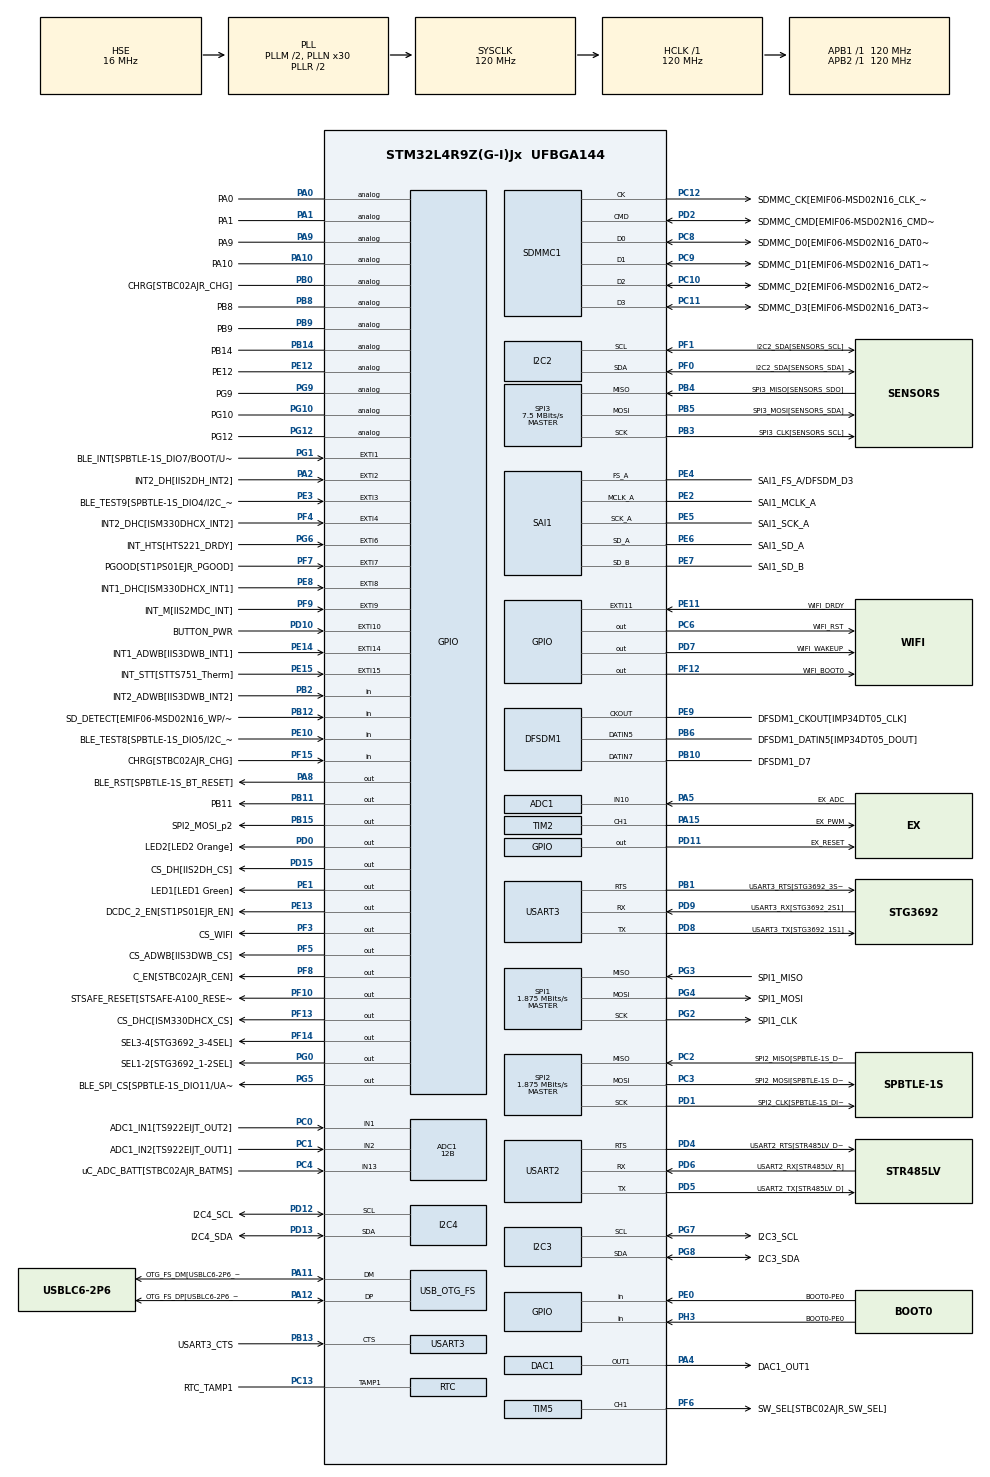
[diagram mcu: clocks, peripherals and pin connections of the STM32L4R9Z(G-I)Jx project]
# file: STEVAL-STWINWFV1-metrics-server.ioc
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PD12.GPIO_Label=I2C4_SCL
ADC1.LowPowerAutoWait=DISABLE
PB10.GPIO_PuPd=GPIO_PULLDOWN
PG8.Signal=I2C3_SDA
PG0.Signal=GPIO_Output
SAI1.Instance-SAI_A_MasterWithClock=SAI$Index_Block_A
PA15\ (JTDI).Signal=S_TIM2_CH1
PC15-OSC32_OUT\ (PC15).Mode=LSE-External-Oscillator
PC14-OSC32_IN\ (PC14).Mode=LSE-External-Oscillator
PF7.Signal=GPXTI7
SPI1.Direction=SPI_DIRECTION_2LINES
RCC.APB2TimFreq_Value=120000000
PB6.Signal=S_DATAIN5DFSDM1
Dma.ADC1.0.Direction=DMA_PERIPH_TO_MEMORY
SPI1.CalculateBaudRate=1.875 MBits/s
PD0.Signal=GPIO_Output
PD8.Signal=USART3_TX
PE1.Signal=GPIO_Output
Dma.ADC1.0.MemDataAlignment=DMA_MDATAALIGN_HALFWORD
ADC1.ScanConvMode=ADC_SCAN_DISABLE
PF1.GPIO_Label=I2C2_SDA[SENSORS_SCL]
PG2.Mode=Full_Duplex_Master
RCC.RTCClockSelection=RCC_RTCCLKSOURCE_LSE
PD1.GPIO_Label=SPI2_CLK[SPBTLE-1S_DIO0/SPI_CLK]
PB12.GPIO_Label=SD_DETECT[EMIF06-MSD02N16_WP/CD]
PF12.GPIO_Label=WIFI_BOOT0
PA13\ (JTMS/SWDIO).GPIO_Label=SWDIO
PC4.GPIO_Label=uC_ADC_BATT[STBC02AJR_BATMS]
PE9.Signal=S_CKOUTDFSDM1
PB1.GPIO_Label=USART3_RTS[STG3692_3S2]
SPI1.DataSize=SPI_DATASIZE_8BIT
PE4.GPIO_Label=SAI1_FS_A/DFSDM_D3
PG4.GPIO_Label=SPI1_MOSI
PC9.Mode=SD_4_bits_Wide_bus
PA8.Signal=GPIO_Output
LTDC.HSync=1
PA0.Signal=GPIO_Analog
PG3.Mode=Full_Duplex_Master
Mcu.Package=UFBGA144
PB9.Signal=GPIO_Analog
PB1.Signal=USART3_RTS
SPI2.Mode=SPI_MODE_MASTER
ADC1.OversamplingMode=DISABLE
SPI3.Mode=SPI_MODE_MASTER
PD12.Signal=I2C4_SCL
PA10.Signal=GPIO_Analog
PE12.GPIO_Label=PE12
PC11.Mode=SD_4_bits_Wide_bus
LTDC.VSync=1
RCC.APB1TimFreq_Value=120000000
PB13.Mode=CTS_RTS
PA4.GPIO_Label=DAC1_OUT1
ADC1.EOCSelection=ADC_EOC_SINGLE_CONV
SAI1.Synchro-SAI_A_MasterWithClock=SAI_ASYNCHRONOUS
PD15.Signal=GPIO_Output
RCC.HSI48_VALUE=48000000
PG12.Signal=GPIO_Analog
SH.S_DATAIN5DFSDM1.0=DFSDM1_DATIN5,PDM_SPI_input_from_ch5_and_internal_clock
TIM5.Channel-Forced\ Output1\ CH1=TIM_CHANNEL_1
SAI1.MClockEnable-SAI_A_MasterWithClock=SAI_MASTERCLOCK_ENABLE
PG5.Signal=GPIO_Output
ADC1.OffsetNumber-0\#ChannelRegularConversion=ADC_OFFSET_NONE
PC13.Signal=RTC_TAMP1
PB6.GPIO_PuPd=GPIO_PULLDOWN
PC2.Signal=SPI2_MISO
SAI1.ErrorAudioFreq-SAI_A_MasterWithClock=-75.0 %
SPI1.CLKPhase=SPI_PHASE_2EDGE
PD6.Mode=Asynchronous
PF8.GPIO_Label=C_EN[STBC02AJR_CEN]
PD10.Signal=GPXTI10
PB8.GPIO_Label=PB8
PA8.GPIO_Label=BLE_RST[SPBTLE-1S_BT_RESET]
SH.COMP_DAC11_group.0=DAC1_OUT1,DAC_OUT1
PE8.GPIO_Label=INT1_DHC[ISM330DHCX_INT1]
Dma.ADC1.0.Priority=DMA_PRIORITY_MEDIUM
NVIC.I2C2_ER_IRQn=true\:0\:0\:false\:false\:true\:true\:true
PD8.Mode=Asynchronous
SAI1.VirtualMode-SAI_A_MasterWithClock=VM_MASTER
PB14.Signal=GPIO_Analog
PA5.Signal=ADCx_IN10
PC12.Mode=SD_4_bits_Wide_bus
PE1.GPIO_Label=LED1[LED1 Green]
PD1.Mode=Full_Duplex_Master
NVIC.DFSDM1_FLT0_IRQn=true\:0\:0\:false\:false\:true\:true\:true
PE14.Signal=GPXTI14
PE6.Mode=SAI_A_MasterWithClock
PB15.GPIO_Label=SPI2_MOSI_p2
SPI1.Mode=SPI_MODE_MASTER
PG7.GPIO_Label=I2C3_SCL
PF4.GPIO_Label=INT2_DHC[ISM330DHCX_INT2]
PA1.GPIO_Label=PA1
PF13.Signal=GPIO_Output
ADC1.ExternalTrigConv=ADC_SOFTWARE_START
PC8.Mode=SD_4_bits_Wide_bus
ADC1.master=1
PA5.GPIO_Label=EX_ADC
PE5.GPIO_Label=SAI1_SCK_A
PC12.GPIO_Label=SDMMC_CK[EMIF06-MSD02N16_CLK_In]
Dma.ADC1.0.RequestNumber=1
ProjectManager.HeapSize=0x200
PB1.Mode=CTS_RTS
NVIC.PriorityGroup=NVIC_PRIORITYGROUP_4
PF0.GPIO_Label=I2C2_SDA[SENSORS_SDA]
PE3.Signal=GPXTI3
PF4.Signal=GPXTI4
PD2.Signal=SDMMC1_CMD
Mcu.Family=STM32L4
PG8.Mode=I2C
ADC1.Overrun=ADC_OVR_DATA_PRESERVED
ADC1.ContinuousConvMode=DISABLE
PG2.Signal=SPI1_SCK
PH0-OSC_IN\ (PH0).Signal=RCC_OSC_IN
Dma.ADC1.0.Polarity=HAL_DMAMUX_REQUEST_GEN_RISING
PE11.GPIO_Label=WIFI_DRDY
VP_TIM5_VS_OPM.Mode=OPM_bit
PA0.GPIO_Label=PA0
PD0.GPIO_Label=LED2[LED2 Orange]
PA11.Mode=Device_Only
I2C2.Timeout=0x000085B8
PG5.GPIO_Label=BLE_SPI_CS[SPBTLE-1S_DIO11/UART_RXD]
PB13.GPIO_Label=USART3_CTS
PB15.Signal=GPIO_Output
PD9.Mode=Asynchronous
PD13.Signal=I2C4_SDA
SAI1.VirtualMode-SAI_B_SyncSlave=VM_SLAVE
SPI3.CLKPolarity=SPI_POLARITY_HIGH
ADC1.Resolution=ADC_RESOLUTION_12B
PD5.Mode=Asynchronous
ADC1.Channel-0\#ChannelRegularConversion=ADC_CHANNEL_VREFINT
PH1-OSC_OUT\ (PH1).Mode=HSE-External-Oscillator
RCC.HSE_VALUE=16000000
LTDC.VBP=1
PB5.Mode=Full_Duplex_Master
PC11.GPIO_Label=SDMMC_D3[EMIF06-MSD02N16_DAT3_In]
TIM2.Channel-PWM\ Generation1\ CH1=TIM_CHANNEL_1
PD13.GPIO_Label=I2C4_SDA
PD5.GPIO_Label=USART2_TX[STR485LV_D]
PF8.Signal=GPIO_Output
PG0.GPIO_Label=SEL1-2[STG3692_1-2SEL]
I2C3.Timing=0x307075B1
SH.ADCx_IN1.0=ADC1_IN1,IN1-Single-Ended
PB5.GPIO_Label=SPI3_MOSI[SENSORS_SDA]
SH.S_TIM5_CH1.0=TIM5_CH1,Forced Output1 CH1
PC5.Signal=SYS_WKUP5
RCC.CK48CLockSelection=RCC_USBCLKSOURCE_HSI48
PE7.Signal=SAI1_SD_B
PD6.Signal=USART2_RX
Dma.Request0=ADC1
PF3.GPIO_Label=CS_WIFI
PE2.GPIO_Label=SAI1_MCLK_A
PG2.GPIO_Label=SPI1_CLK
PH1-OSC_OUT\ (PH1).GPIO_Label=OSC_OUT
PB3\ (JTDO/TRACESWO).GPIO_Label=SPI3_CLK[SENSORS_SCL]
RCC.MSI_VALUE=4000000
SH.ADCx_IN13.0=ADC1_IN13,IN13-Single-Ended
SH.S_TIM2_CH1.0=TIM2_CH1,PWM Generation1 CH1
LTDC.VFP=1
PD15.GPIO_Label=CS_DH[IIS2DH_CS]
PG7.Signal=I2C3_SCL
PC9.GPIO_Label=SDMMC_D1[EMIF06-MSD02N16_DAT1_In]
PC11.Signal=SDMMC1_D3
RCC.DSITX_Div=1
PC8.Signal=SDMMC1_D0
PC10.Mode=SD_4_bits_Wide_bus
PC2.Mode=Full_Duplex_Master
PE14.GPIO_Label=INT1_ADWB[IIS3DWB_INT1]
PD9.Signal=USART3_RX
PA12.GPIO_Label=OTG_FS_DP[USBLC6-2P6_D1]
PH1-OSC_OUT\ (PH1).Signal=RCC_OSC_OUT
PD8.GPIO_Label=USART3_TX[STG3692_1S1]
PG8.GPIO_Label=I2C3_SDA
SAI1.RealAudioFreq-SAI_A_MasterWithClock=48.0 KHz
Dma.ADC1.0.PeriphDataAlignment=DMA_PDATAALIGN_HALFWORD
PF6.Signal=S_TIM5_CH1
PB10.GPIO_Label=DFSDM1_D7
ADC1.EnableAnalogWatchDog3=false
ADC1.EnableAnalogWatchDog2=false
ADC1.EnableAnalogWatchDog1=false
RCC.USBFreq_Value=48000000
PF9.GPIO_Label=INT_M[IIS2MDC_INT]
PD10.GPIO_Label=BUTTON_PWR
PA1.Signal=GPIO_Analog
PD2.Mode=SD_4_bits_Wide_bus
board=STEVAL-STWINKT1
SPI3.CLKPhase=SPI_PHASE_2EDGE
RCC.VCOOutputFreq_Value=240000000
PE5.Mode=SAI_A_MasterWithClock
RCC.ADCFreq_Value=76800000
PC1.GPIO_Label=ADC1_IN2[TS922EIJT_OUT1]
RCC.PLLDSIODF=DSI_PLL_OUT_DIV2
PF15.GPIO_Label=CHRG[STBC02AJR_CHG]
PF1.Signal=I2C2_SCL
ADC1.NbrOfConversion=1
PC13.Mode=Tamper 1 enabled
PA15\ (JTDI).GPIO_Label=EX_PWM
PE0.Signal=GPIO_Input
PE7.GPIO_Label=SAI1_SD_B
PE12.Signal=GPIO_Analog
RCC.SYSCLKFreq_VALUE=120000000
PC14-OSC32_IN\ (PC14).Signal=RCC_OSC32_IN
Dma.ADC1.0.MemInc=DMA_MINC_ENABLE
PB2.GPIO_Label=INT2_ADWB[IIS3DWB_INT2]
NVIC.I2C2_EV_IRQn=true\:0\:0\:false\:false\:true\:true\:true
RCC.HSI_VALUE=16000000
PH0-OSC_IN\ (PH0).GPIO_Label=OSC_IN
RCC.PLLN=30
ADC1.DataAlign=ADC_DATAALIGN_RIGHT
DFSDM1.Filter_regChannel_FIL0=DFSDM_CHANNEL_5
PB12.Signal=GPIO_Input
PB4\ (NJTRST).Signal=SPI3_MISO
SPI3.Direction=SPI_DIRECTION_2LINES
SPI3.VirtualType=VM_MASTER
SPI1.VirtualType=VM_MASTER
SPI2.VirtualType=VM_MASTER
PG4.Signal=SPI1_MOSI
PC12.Signal=SDMMC1_CK
PB14.GPIO_Label=PB14
PG6.GPIO_Label=INT_HTS[HTS221_DRDY]
PC6.GPIO_Label=WIFI_RST
VP_RTC_VS_RTC_Activate.Mode=RTC_Enabled
PB6.GPIO_Label=DFSDM1_DATIN5[IMP34DT05_DOUT]
PC5.Mode=SYS_WakeUp4
PB13.Signal=USART3_CTS
PD6.GPIO_Label=USART2_RX[STR485LV_R]
PE6.GPIO_Label=SAI1_SD_A
PF6.GPIO_Label=SW_SEL[STBC02AJR_SW_SEL]
RCC.SYSCLKSource=RCC_SYSCLKSOURCE_PLLCLK
USART3.VirtualMode-Asynchronous=VM_ASYNC
PA14\ (JTCK/SWCLK).Signal=SYS_JTCK-SWCLK
I2C4.Timing=0x307075B1
PE2.Mode=SAI_A_MasterWithClock
PD4.Signal=USART2_RTS
PC3.Signal=SPI2_MOSI
PE5.Signal=SAI1_SCK_A
PF10.GPIO_Label=STSAFE_RESET[STSAFE-A100_RESET]
PB2.Signal=GPIO_Input
VP_ADC1_Vref_Input.Mode=IN-Vrefint
Dma.ADC1.0.PeriphInc=DMA_PINC_DISABLE
SPI2.CalculateBaudRate=1.875 MBits/s
PE2.Signal=SAI1_MCLK_A
PA14\ (JTCK/SWCLK).Mode=Serial_Wire
PF3.Signal=GPIO_Output
PE10.Signal=GPIO_Input
ADC1.SamplingTime-0\#ChannelRegularConversion=ADC_SAMPLETIME_2CYCLES_5
PH3-BOOT0.Signal=GPIO_Input
RCC.SDMMCClockSelection=RCC_SDIOCLKSOURCE_CLK48
ADC1.EnableInjectedConversion=DISABLE
PA14\ (JTCK/SWCLK).GPIO_Label=SWDCLK
PD4.Mode=RTS_Only
PF14.Signal=GPIO_Output
PE10.GPIO_Label=BLE_TEST8[SPBTLE-1S_DIO5/I2C_SDA]
PH0-OSC_IN\ (PH0).Mode=HSE-External-Oscillator
Dma.ADC1.0.EventEnable=DISABLE
Dma.ADC1.0.Instance=DMA1_Channel1
PC15-OSC32_OUT\ (PC15).GPIO_Label=OSC32_OUT
ADC1.Rank-0\#ChannelRegularConversion=1
PD9.GPIO_Label=USART3_RX[STG3692_2S1]
Dma.ADC1.0.SyncRequestNumber=1
PG9.Signal=GPIO_Analog
PA9.GPIO_Label=PA9
PC6.Signal=GPIO_Output
PB11.GPIO_Label=PB11
PD7.Signal=GPIO_Output
PD1.Signal=SPI2_SCK
PA11.GPIO_Label=OTG_FS_DM[USBLC6-2P6_D2]
PF14.GPIO_Label=SEL3-4[STG3692_3-4SEL]
ADC1.ExternalTrigConvEdge=ADC_EXTERNALTRIGCONVEDGE_NONE
PC0.Signal=ADCx_IN1
PF13.GPIO_Label=CS_DHC[ISM330DHCX_CS]
PG10.Signal=GPIO_Analog
PC14-OSC32_IN\ (PC14).GPIO_Label=OSC32_IN
PF1.Mode=I2C
Dma.ADC1.0.SignalID=NONE
PA9.Signal=GPIO_Analog
PE9.GPIO_Label=DFSDM1_CKOUT[IMP34DT05_CLK]
PB10.Signal=S_DATAIN7DFSDM1
PE15.Signal=GPXTI15
PE8.Signal=GPXTI8
ADC1.DMAContinuousRequests=DISABLE
PB4\ (NJTRST).Mode=Full_Duplex_Master
PA4.Signal=COMP_DAC11_group
PB5.Signal=SPI3_MOSI
PD12.Mode=I2C
PE13.GPIO_Label=DCDC_2_EN[ST1PS01EJR_EN]
PD11.Signal=GPIO_Output
PA11.Signal=USB_OTG_FS_DM
PF9.Signal=GPXTI9
PB3\ (JTDO/TRACESWO).Mode=Full_Duplex_Master
ADC1.EnableRegularConversion=ENABLE
PC3.GPIO_Label=SPI2_MOSI[SPBTLE-1S_DIO3/SPI_MOSI]
SPI2.DataSize=SPI_DATASIZE_8BIT
PB4\ (NJTRST).GPIO_Label=SPI3_MISO[SENSORS_SDO]
NVIC.DMA1_Channel1_IRQn=true\:0\:0\:false\:false\:true\:false\:true
PG3.GPIO_Label=SPI1_MISO
PB6.GPIO_Speed=GPIO_SPEED_FREQ_VERY_HIGH
PB0.Signal=GPIO_Analog
PC1.Signal=ADCx_IN2
PD2.GPIO_Label=SDMMC_CMD[EMIF06-MSD02N16_CMD_In]
PG10.GPIO_Label=PG10
PA13\ (JTMS/SWDIO).Signal=SYS_JTMS-SWDIO
PF6.GPIO_Speed=GPIO_SPEED_FREQ_HIGH
PC3.Mode=Full_Duplex_Master
RCC.CortexFreq_Value=120000000
PG6.Signal=GPXTI6
PB10.GPIO_Speed=GPIO_SPEED_FREQ_VERY_HIGH
LTDC.HBP=1
SH.ADCx_IN2.0=ADC1_IN2,IN2-Single-Ended
PC10.Signal=SDMMC1_D2
I2C2.Timing=0x307075B1
PH3-BOOT0.GPIO_Label=BOOT0-PE0
PC0.GPIO_Label=ADC1_IN1[TS922EIJT_OUT2]
PE9.GPIO_Speed=GPIO_SPEED_FREQ_VERY_HIGH
PB0.GPIO_Label=CHRG[STBC02AJR_CHG]
PC13.GPIO_Label=RTC_TAMP1
PB11.Signal=GPIO_Output
ProjectManager.StackSize=0x400
PA12.Signal=USB_OTG_FS_DP
SPI2.CLKPolarity=SPI_POLARITY_LOW
PG4.Mode=Full_Duplex_Master
PD11.GPIO_Label=EX_RESET 
RCC.HCLKFreq_Value=120000000
PF12.Signal=GPIO_Output
RCC.AHBFreq_Value=120000000
SPI2.BaudRatePrescaler=SPI_BAUDRATEPRESCALER_64
SPI3.DataSize=SPI_DATASIZE_8BIT
USART2.VirtualMode-Asynchronous=VM_ASYNC
SH.S_DATAIN7DFSDM1.0=DFSDM1_DATIN7,PDM_SPI_input_from_ch7_and_internal_clock
PE13.Signal=GPIO_Output
PF7.GPIO_Label=PGOOD[ST1PS01EJR_PGOOD]
PA10.GPIO_Label=PA10
LTDC.HFP=1
PE4.Mode=SAI_A_MasterWithClock
LTDC.ActiveW=800
PE4.Signal=SAI1_FS_A
PD7.GPIO_Label=WIFI_WAKEUP
PA2.GPIO_Label=INT2_DH[IIS2DH_INT2]
PF5.GPIO_Label=CS_ADWB[IIS3DWB_CS]
USB_OTG_FS.VirtualMode=Device_Only
SPI2.CLKPhase=SPI_PHASE_2EDGE
PE0.GPIO_Label=BOOT0-PE0
PF5.Signal=GPIO_Output
SAI1.Synchro-SAI_B_SyncSlave=SAI_SYNCHRONOUS
SPI2.Direction=SPI_DIRECTION_2LINES
PF0.Signal=I2C2_SDA
SPI1.BaudRatePrescaler=SPI_BAUDRATEPRESCALER_64
PC2.GPIO_Label=SPI2_MISO[SPBTLE-1S_DIO2/SPI_MISO]
RCC.PLLSAI1R=RCC_PLLR_DIV4
RCC.PLLSAI1P=RCC_PLLP_DIV25
RCC.PLLSAI1Q=RCC_PLLQ_DIV4
RCC.PLLSAI1N=96
RCC.PLLSourceVirtual=RCC_PLLSOURCE_HSE
PA13\ (JTMS/SWDIO).Mode=Serial_Wire
PB9.GPIO_Label=PB9
PC10.GPIO_Label=SDMMC_D2[EMIF06-MSD02N16_DAT2_In]
PG3.Signal=SPI1_MISO
PG1.Signal=GPXTI1
PC4.Signal=ADCx_IN13
ADC1.DiscontinuousConvMode=DISABLE
PD5.Signal=USART2_TX
PC15-OSC32_OUT\ (PC15).Signal=RCC_OSC32_OUT
PC8.GPIO_Label=SDMMC_D0[EMIF06-MSD02N16_DAT0_In]
PE15.GPIO_Label=INT_STT[STTS751_Therm]
PB3\ (JTDO/TRACESWO).Signal=SPI3_SCK
ProjectManager.TargetToolchain=STM32CubeIDE
Dma.ADC1.0.Mode=DMA_CIRCULAR
Dma.ADC1.0.SyncSignalID=NONE
PD13.Mode=I2C
PF2.Signal=I2C2_SMBA
PG7.Mode=I2C
PE11.Signal=GPXTI11
PG9.GPIO_Label=PG9
PG1.GPIO_Label=BLE_INT[SPBTLE-1S_DIO7/BOOT/UART_CTS]
Dma.ADC1.0.SyncPolarity=HAL_DMAMUX_SYNC_NO_EVENT
RCC.APB2Freq_Value=120000000
SPI3.CalculateBaudRate=7.5 MBits/s
PD4.GPIO_Label=USART2_RTS[STR485LV_DE]
PF10.Signal=GPIO_Output
SH.S_CKOUTDFSDM1.0=DFSDM1_CKOUT,PDM_SPI_input_from_ch7_and_internal_clock
SH.S_CKOUTDFSDM1.1=DFSDM1_CKOUT,PDM_SPI_input_from_ch5_and_internal_clock
SPI3.BaudRatePrescaler=SPI_BAUDRATEPRESCALER_16
SH.S_CKOUTDFSDM1.2=DFSDM1_CKOUT,CKOUT
PF15.Signal=GPIO_Input
PE6.Signal=SAI1_SD_A
Mcu.Name=STM32L4R9Z(G-I)Jx
PA2.Signal=GPXTI2
PE7.Mode=SAI_B_SyncSlave
RCC.PLLM2=5
RCC.PLLM1=2
RCC.PLLM3=2
PA12.Mode=Device_Only
PC5.GPIO_Label=PC5/WKUP5
SAI1.Instance-SAI_B_SyncSlave=SAI$Index_Block_B
Dma.ADC1.0.SyncEnable=DISABLE
SH.ADCx_IN10.0=ADC1_IN10,IN10-Single-Ended
PF0.Mode=I2C
PG12.GPIO_Label=PG12
VP_LTDC_DSIMode.Mode=RGB888
ADC1.NbrOfConversionFlag=1
PB8.Signal=GPIO_Analog
PE3.GPIO_Label=BLE_TEST9[SPBTLE-1S_DIO4/I2C_CLK]
PC9.Signal=SDMMC1_D1
RCC.APB1Freq_Value=120000000
ADC1.ClockPrescaler=ADC_CLOCK_ASYNC_DIV1
PE9.GPIO_PuPd=GPIO_PULLDOWN
PF2.GPIO_Label=I2C2_SMBA[STTS751_EV]

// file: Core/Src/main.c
/* USER CODE BEGIN Header */
/**
  ******************************************************************************
  * @file           : main.c
  * @brief          : Main program body
  ******************************************************************************
  * @attention
  *
  * <h2><center>&copy; Copyright (c) 2021 STMicroelectronics.
  * All rights reserved.</center></h2>
  *
  * This software component is licensed by ST under BSD 3-Clause license,
  * the "License"; You may not use this file except in compliance with the
  * License. You may obtain a copy of the License at:
  *                        opensource.org/licenses/BSD-3-Clause
  *
  ******************************************************************************
  */
/* USER CODE END Header */
#include "main.h"

/* USER CODE BEGIN PTD */
typedef union {
  int16_t i16bit;
  uint8_t u8bit[2];
} axis1bit16_t;

typedef union {
  int32_t i32bit;
  uint8_t u8bit[4];
} axis1bit32_t;

typedef union {
  int16_t i16bit[3];
  uint8_t u8bit[6];
} axis3bit16_t;
/* USER CODE END PTD */

/* USER CODE BEGIN PM */
typedef struct {
	float x0;
	float y0;
	float x1;
	float y1;
} lin_t;

float linear_interpolation(lin_t *lin, int16_t x) {
	return ((lin->y1 - lin->y0) * x + ((lin->x1 * lin->y0) - (lin->x0 * lin->y1))) / (lin->x1 - lin->x0);
}
/* USER CODE END PM */

ADC_HandleTypeDef hadc1;
DMA_HandleTypeDef hdma_adc1;

DAC_HandleTypeDef hdac1;

DFSDM_Filter_HandleTypeDef hdfsdm1_filter0;
DFSDM_Channel_HandleTypeDef hdfsdm1_channel5;
DFSDM_Channel_HandleTypeDef hdfsdm1_channel7;

I2C_HandleTypeDef hi2c2;
I2C_HandleTypeDef hi2c3;
I2C_HandleTypeDef hi2c4;

LTDC_HandleTypeDef hltdc;

RTC_HandleTypeDef hrtc;

SAI_HandleTypeDef hsai_BlockA1;
SAI_HandleTypeDef hsai_BlockB1;

SD_HandleTypeDef hsd1;

SPI_HandleTypeDef hspi1;
SPI_HandleTypeDef hspi2;
SPI_HandleTypeDef hspi3;

TIM_HandleTypeDef htim2;
TIM_HandleTypeDef htim5;

UART_HandleTypeDef huart2;
UART_HandleTypeDef huart3;

PCD_HandleTypeDef hpcd_USB_OTG_FS;

/* USER CODE BEGIN PV */
static uint8_t whoamI;
lin_t lin_hum;
lin_t lin_temp;
stmdev_ctx_t hts221Driver;
/* USER CODE END PV */

void SystemClock_Config(void);
static void MX_GPIO_Init(void);
static void MX_DMA_Init(void);
static void MX_ADC1_Init(void);
static void MX_DAC1_Init(void);
static void MX_DFSDM1_Init(void);
static void MX_I2C2_Init(void);
static void MX_I2C3_Init(void);
static void MX_I2C4_Init(void);
static void MX_LTDC_Init(void);
static void MX_RTC_Init(void);
static void MX_SAI1_Init(void);
static void MX_SDMMC1_SD_Init(void);
static void MX_SPI1_Init(void);
static void MX_SPI2_Init(void);
static void MX_SPI3_Init(void);
static void MX_TIM2_Init(void);
static void MX_TIM5_Init(void);
static void MX_USART2_UART_Init(void);
static void MX_USART3_UART_Init(void);
static void MX_USB_OTG_FS_PCD_Init(void);
/* USER CODE BEGIN PFP */
HAL_StatusTypeDef Init_HTS221(void);
static int32_t hts221_read(void *handle, uint8_t reg, uint8_t *bufp, uint16_t len);
static int32_t hts221_write(void *handle, uint8_t reg, uint8_t *bufp, uint16_t len);
/* USER CODE END PFP */

int main(void)
{
  /* USER CODE BEGIN 1 */
  hts221_reg_t reg_HTS221;
  static axis1bit16_t data_raw_temperature_HTS221;
  static float temperature_degC_HTS221;
  uint8_t buf[12];
  /* USER CODE END 1 */

  /* MCU Configuration--------------------------------------------------------*/

  /* Reset of all peripherals, Initializes the Flash interface and the Systick. */

  HAL_Init();

  /* Configure the system clock */
  SystemClock_Config();

  /* Initialize all configured peripherals */
  MX_GPIO_Init();
  MX_DMA_Init();
  MX_ADC1_Init();
  MX_DAC1_Init();
  MX_DFSDM1_Init();
  MX_I2C2_Init();
  MX_I2C3_Init();
  MX_I2C4_Init();
  MX_LTDC_Init();
  MX_RTC_Init();
  MX_SAI1_Init();
  MX_SDMMC1_SD_Init();
  MX_SPI1_Init();
  MX_SPI2_Init();
  MX_SPI3_Init();
  MX_TIM2_Init();
  MX_TIM5_Init();
  MX_USART2_UART_Init();
  MX_USART3_UART_Init();
  MX_USB_OTG_FS_PCD_Init();
  /* USER CODE BEGIN 2 */
  hts221Driver.handle = &hi2c2;
  hts221Driver.read_reg = hts221_read;
  hts221Driver.write_reg = hts221_write;

  Init_HTS221();
  /* USER CODE END 2 */

  /* Infinite loop */
  while (1)
  {

    /* USER CODE BEGIN 3 */
    if (reg_HTS221.status_reg.t_da) {
      memset(data_raw_temperature_HTS221.u8bit, 0x00, sizeof(int16_t));
      hts221_temperature_raw_get(&hts221Driver, data_raw_temperature_HTS221.u8bit);
      temperature_degC_HTS221 = linear_interpolation(&lin_temp, data_raw_temperature_HTS221.i16bit);
    }
    sprintf((char*)buf, "%f °C\r\n", temperature_degC_HTS221);
    HAL_UART_Transmit(&huart2, buf, strlen((char*)buf), HAL_MAX_DELAY);
    HAL_Delay(1000);
  }
  /* USER CODE END 3 */
}

void SystemClock_Config(void)
{
  RCC_OscInitTypeDef RCC_OscInitStruct = {0};
  RCC_ClkInitTypeDef RCC_ClkInitStruct = {0};
  RCC_PeriphCLKInitTypeDef PeriphClkInit = {0};

  /** Configure the main internal regulator output voltage
  */
  if (HAL_PWREx_ControlVoltageScaling(PWR_REGULATOR_VOLTAGE_SCALE1_BOOST) != HAL_OK)
  {
    Error_Handler();
  }
  /** Configure LSE Drive Capability
  */
  HAL_PWR_EnableBkUpAccess();
  __HAL_RCC_LSEDRIVE_CONFIG(RCC_LSEDRIVE_LOW);
  /** Initializes the RCC Oscillators according to the specified parameters
  * in the RCC_OscInitTypeDef structure.
  */
  RCC_OscInitStruct.OscillatorType = RCC_OSCILLATORTYPE_HSI48|RCC_OSCILLATORTYPE_HSE
                              |RCC_OSCILLATORTYPE_LSE;
  RCC_OscInitStruct.HSEState = RCC_HSE_ON;
  RCC_OscInitStruct.LSEState = RCC_LSE_ON;
  RCC_OscInitStruct.HSI48State = RCC_HSI48_ON;
  RCC_OscInitStruct.PLL.PLLState = RCC_PLL_ON;
  RCC_OscInitStruct.PLL.PLLSource = RCC_PLLSOURCE_HSE;
  RCC_OscInitStruct.PLL.PLLM = 2;
  RCC_OscInitStruct.PLL.PLLN = 30;
  RCC_OscInitStruct.PLL.PLLP = RCC_PLLP_DIV2;
  RCC_OscInitStruct.PLL.PLLQ = RCC_PLLQ_DIV2;
  RCC_OscInitStruct.PLL.PLLR = RCC_PLLR_DIV2;
  if (HAL_RCC_OscConfig(&RCC_OscInitStruct) != HAL_OK)
  {
    Error_Handler();
  }
  /** Initializes the CPU, AHB and APB buses clocks
  */
  RCC_ClkInitStruct.ClockType = RCC_CLOCKTYPE_HCLK|RCC_CLOCKTYPE_SYSCLK
                              |RCC_CLOCKTYPE_PCLK1|RCC_CLOCKTYPE_PCLK2;
  RCC_ClkInitStruct.SYSCLKSource = RCC_SYSCLKSOURCE_PLLCLK;
  RCC_ClkInitStruct.AHBCLKDivider = RCC_SYSCLK_DIV1;
  RCC_ClkInitStruct.APB1CLKDivider = RCC_HCLK_DIV1;
  RCC_ClkInitStruct.APB2CLKDivider = RCC_HCLK_DIV1;

  if (HAL_RCC_ClockConfig(&RCC_ClkInitStruct, FLASH_LATENCY_5) != HAL_OK)
  {
    Error_Handler();
  }
  PeriphClkInit.PeriphClockSelection = RCC_PERIPHCLK_RTC|RCC_PERIPHCLK_USART2
                              |RCC_PERIPHCLK_USART3|RCC_PERIPHCLK_SAI1
                              |RCC_PERIPHCLK_I2C2|RCC_PERIPHCLK_I2C3
                              |RCC_PERIPHCLK_I2C4|RCC_PERIPHCLK_DFSDM1
                              |RCC_PERIPHCLK_USB|RCC_PERIPHCLK_SDMMC1
                              |RCC_PERIPHCLK_ADC|RCC_PERIPHCLK_LTDC;
  PeriphClkInit.Usart2ClockSelection = RCC_USART2CLKSOURCE_PCLK1;
  PeriphClkInit.Usart3ClockSelection = RCC_USART3CLKSOURCE_PCLK1;
  PeriphClkInit.I2c2ClockSelection = RCC_I2C2CLKSOURCE_PCLK1;
  PeriphClkInit.I2c3ClockSelection = RCC_I2C3CLKSOURCE_PCLK1;
  PeriphClkInit.I2c4ClockSelection = RCC_I2C4CLKSOURCE_PCLK1;
  PeriphClkInit.Sai1ClockSelection = RCC_SAI1CLKSOURCE_PLLSAI1;
  PeriphClkInit.AdcClockSelection = RCC_ADCCLKSOURCE_PLLSAI1;
  PeriphClkInit.Dfsdm1ClockSelection = RCC_DFSDM1CLKSOURCE_PCLK;
  PeriphClkInit.RTCClockSelection = RCC_RTCCLKSOURCE_LSE;
  PeriphClkInit.UsbClockSelection = RCC_USBCLKSOURCE_HSI48;
  PeriphClkInit.Sdmmc1ClockSelection = RCC_SDMMC1CLKSOURCE_HSI48;
  PeriphClkInit.LtdcClockSelection = RCC_LTDCCLKSOURCE_PLLSAI2_DIV2;
  PeriphClkInit.PLLSAI2.PLLSAI2Source = RCC_PLLSOURCE_HSE;
  PeriphClkInit.PLLSAI2.PLLSAI2M = 2;
  PeriphClkInit.PLLSAI2.PLLSAI2N = 8;
  PeriphClkInit.PLLSAI2.PLLSAI2P = RCC_PLLP_DIV2;
  PeriphClkInit.PLLSAI2.PLLSAI2R = RCC_PLLR_DIV2;
  PeriphClkInit.PLLSAI2.PLLSAI2Q = RCC_PLLQ_DIV2;
  PeriphClkInit.PLLSAI2.PLLSAI2ClockOut = RCC_PLLSAI2_LTDCCLK;
  PeriphClkInit.PLLSAI1.PLLSAI1Source = RCC_PLLSOURCE_HSE;
  PeriphClkInit.PLLSAI1.PLLSAI1M = 5;
  PeriphClkInit.PLLSAI1.PLLSAI1N = 96;
  PeriphClkInit.PLLSAI1.PLLSAI1P = RCC_PLLP_DIV25;
  PeriphClkInit.PLLSAI1.PLLSAI1Q = RCC_PLLQ_DIV4;
  PeriphClkInit.PLLSAI1.PLLSAI1R = RCC_PLLR_DIV4;
  PeriphClkInit.PLLSAI1.PLLSAI1ClockOut = RCC_PLLSAI1_SAI1CLK|RCC_PLLSAI1_ADC1CLK;
  if (HAL_RCCEx_PeriphCLKConfig(&PeriphClkInit) != HAL_OK)
  {
    Error_Handler();
  }
}

static void MX_ADC1_Init(void)
{

  ADC_ChannelConfTypeDef sConfig = {0};

  /** Common config
  */
  hadc1.Instance = ADC1;
  hadc1.Init.ClockPrescaler = ADC_CLOCK_ASYNC_DIV1;
  hadc1.Init.Resolution = ADC_RESOLUTION_12B;
  hadc1.Init.DataAlign = ADC_DATAALIGN_RIGHT;
  hadc1.Init.ScanConvMode = ADC_SCAN_DISABLE;
  hadc1.Init.EOCSelection = ADC_EOC_SINGLE_CONV;
  hadc1.Init.LowPowerAutoWait = DISABLE;
  hadc1.Init.ContinuousConvMode = DISABLE;
  hadc1.Init.NbrOfConversion = 1;
  hadc1.Init.DiscontinuousConvMode = DISABLE;
  hadc1.Init.ExternalTrigConv = ADC_SOFTWARE_START;
  hadc1.Init.ExternalTrigConvEdge = ADC_EXTERNALTRIGCONVEDGE_NONE;
  hadc1.Init.DMAContinuousRequests = DISABLE;
  hadc1.Init.Overrun = ADC_OVR_DATA_PRESERVED;
  hadc1.Init.OversamplingMode = DISABLE;
  if (HAL_ADC_Init(&hadc1) != HAL_OK)
  {
    Error_Handler();
  }
  /** Configure Regular Channel
  */
  sConfig.Channel = ADC_CHANNEL_VREFINT;
  sConfig.Rank = ADC_REGULAR_RANK_1;
  sConfig.SamplingTime = ADC_SAMPLETIME_2CYCLES_5;
  sConfig.SingleDiff = ADC_SINGLE_ENDED;
  sConfig.OffsetNumber = ADC_OFFSET_NONE;
  sConfig.Offset = 0;
  if (HAL_ADC_ConfigChannel(&hadc1, &sConfig) != HAL_OK)
  {
    Error_Handler();
  }

}

static void MX_DAC1_Init(void)
{

  DAC_ChannelConfTypeDef sConfig = {0};

  /** DAC Initialization
  */
  hdac1.Instance = DAC1;
  if (HAL_DAC_Init(&hdac1) != HAL_OK)
  {
    Error_Handler();
  }
  /** DAC channel OUT1 config
  */
  sConfig.DAC_SampleAndHold = DAC_SAMPLEANDHOLD_DISABLE;
  sConfig.DAC_Trigger = DAC_TRIGGER_NONE;
  sConfig.DAC_HighFrequency = DAC_HIGH_FREQUENCY_INTERFACE_MODE_DISABLE;
  sConfig.DAC_OutputBuffer = DAC_OUTPUTBUFFER_ENABLE;
  sConfig.DAC_ConnectOnChipPeripheral = DAC_CHIPCONNECT_DISABLE;
  sConfig.DAC_UserTrimming = DAC_TRIMMING_FACTORY;
  if (HAL_DAC_ConfigChannel(&hdac1, &sConfig, DAC_CHANNEL_1) != HAL_OK)
  {
    Error_Handler();
  }

}

static void MX_DFSDM1_Init(void)
{

  hdfsdm1_filter0.Instance = DFSDM1_Filter0;
  hdfsdm1_filter0.Init.RegularParam.Trigger = DFSDM_FILTER_SW_TRIGGER;
  hdfsdm1_filter0.Init.RegularParam.FastMode = DISABLE;
  hdfsdm1_filter0.Init.RegularParam.DmaMode = DISABLE;
  hdfsdm1_filter0.Init.FilterParam.SincOrder = DFSDM_FILTER_FASTSINC_ORDER;
  hdfsdm1_filter0.Init.FilterParam.Oversampling = 1;
  hdfsdm1_filter0.Init.FilterParam.IntOversampling = 1;
  if (HAL_DFSDM_FilterInit(&hdfsdm1_filter0) != HAL_OK)
  {
    Error_Handler();
  }
  hdfsdm1_channel5.Instance = DFSDM1_Channel5;
  hdfsdm1_channel5.Init.OutputClock.Activation = ENABLE;
  hdfsdm1_channel5.Init.OutputClock.Selection = DFSDM_CHANNEL_OUTPUT_CLOCK_SYSTEM;
  hdfsdm1_channel5.Init.OutputClock.Divider = 2;
  hdfsdm1_channel5.Init.Input.Multiplexer = DFSDM_CHANNEL_EXTERNAL_INPUTS;
  hdfsdm1_channel5.Init.Input.DataPacking = DFSDM_CHANNEL_STANDARD_MODE;
  hdfsdm1_channel5.Init.Input.Pins = DFSDM_CHANNEL_SAME_CHANNEL_PINS;
  hdfsdm1_channel5.Init.SerialInterface.Type = DFSDM_CHANNEL_SPI_RISING;
  hdfsdm1_channel5.Init.SerialInterface.SpiClock = DFSDM_CHANNEL_SPI_CLOCK_INTERNAL;
  hdfsdm1_channel5.Init.Awd.FilterOrder = DFSDM_CHANNEL_FASTSINC_ORDER;
  hdfsdm1_channel5.Init.Awd.Oversampling = 1;
  hdfsdm1_channel5.Init.Offset = 0;
  hdfsdm1_channel5.Init.RightBitShift = 0x00;
  if (HAL_DFSDM_ChannelInit(&hdfsdm1_channel5) != HAL_OK)
  {
    Error_Handler();
  }
  hdfsdm1_channel7.Instance = DFSDM1_Channel7;
  hdfsdm1_channel7.Init.OutputClock.Activation = ENABLE;
  hdfsdm1_channel7.Init.OutputClock.Selection = DFSDM_CHANNEL_OUTPUT_CLOCK_SYSTEM;
  hdfsdm1_channel7.Init.OutputClock.Divider = 2;
  hdfsdm1_channel7.Init.Input.Multiplexer = DFSDM_CHANNEL_EXTERNAL_INPUTS;
  hdfsdm1_channel7.Init.Input.DataPacking = DFSDM_CHANNEL_STANDARD_MODE;
  hdfsdm1_channel7.Init.Input.Pins = DFSDM_CHANNEL_SAME_CHANNEL_PINS;
  hdfsdm1_channel7.Init.SerialInterface.Type = DFSDM_CHANNEL_SPI_RISING;
  hdfsdm1_channel7.Init.SerialInterface.SpiClock = DFSDM_CHANNEL_SPI_CLOCK_INTERNAL;
  hdfsdm1_channel7.Init.Awd.FilterOrder = DFSDM_CHANNEL_FASTSINC_ORDER;
  hdfsdm1_channel7.Init.Awd.Oversampling = 1;
  hdfsdm1_channel7.Init.Offset = 0;
  hdfsdm1_channel7.Init.RightBitShift = 0x00;
  if (HAL_DFSDM_ChannelInit(&hdfsdm1_channel7) != HAL_OK)
  {
    Error_Handler();
  }
  if (HAL_DFSDM_FilterConfigRegChannel(&hdfsdm1_filter0, DFSDM_CHANNEL_5, DFSDM_CONTINUOUS_CONV_ON) != HAL_OK)
  {
    Error_Handler();
  }

}

static void MX_I2C2_Init(void)
{

  hi2c2.Instance = I2C2;
  hi2c2.Init.Timing = 0x307075B1;
  hi2c2.Init.OwnAddress1 = 0;
  hi2c2.Init.AddressingMode = I2C_ADDRESSINGMODE_7BIT;
  hi2c2.Init.DualAddressMode = I2C_DUALADDRESS_DISABLE;
  hi2c2.Init.OwnAddress2 = 0;
  hi2c2.Init.OwnAddress2Masks = I2C_OA2_NOMASK;
  hi2c2.Init.GeneralCallMode = I2C_GENERALCALL_DISABLE;
  hi2c2.Init.NoStretchMode = I2C_NOSTRETCH_DISABLE;
  if (HAL_I2C_Init(&hi2c2) != HAL_OK)
  {
    Error_Handler();
  }
  /** Configure Analogue filter
  */
  if (HAL_I2CEx_ConfigAnalogFilter(&hi2c2, I2C_ANALOGFILTER_ENABLE) != HAL_OK)
  {
    Error_Handler();
  }
  /** Configure Digital filter
  */
  if (HAL_I2CEx_ConfigDigitalFilter(&hi2c2, 0) != HAL_OK)
  {
    Error_Handler();
  }

}

static void MX_I2C3_Init(void)
{

  hi2c3.Instance = I2C3;
  hi2c3.Init.Timing = 0x307075B1;
  hi2c3.Init.OwnAddress1 = 0;
  hi2c3.Init.AddressingMode = I2C_ADDRESSINGMODE_7BIT;
  hi2c3.Init.DualAddressMode = I2C_DUALADDRESS_DISABLE;
  hi2c3.Init.OwnAddress2 = 0;
  hi2c3.Init.OwnAddress2Masks = I2C_OA2_NOMASK;
  hi2c3.Init.GeneralCallMode = I2C_GENERALCALL_DISABLE;
  hi2c3.Init.NoStretchMode = I2C_NOSTRETCH_DISABLE;
  if (HAL_I2C_Init(&hi2c3) != HAL_OK)
  {
    Error_Handler();
  }
  /** Configure Analogue filter
  */
  if (HAL_I2CEx_ConfigAnalogFilter(&hi2c3, I2C_ANALOGFILTER_ENABLE) != HAL_OK)
  {
    Error_Handler();
  }
  /** Configure Digital filter
  */
  if (HAL_I2CEx_ConfigDigitalFilter(&hi2c3, 0) != HAL_OK)
  {
    Error_Handler();
  }

}

static void MX_I2C4_Init(void)
{

  hi2c4.Instance = I2C4;
  hi2c4.Init.Timing = 0x307075B1;
  hi2c4.Init.OwnAddress1 = 0;
  hi2c4.Init.AddressingMode = I2C_ADDRESSINGMODE_7BIT;
  hi2c4.Init.DualAddressMode = I2C_DUALADDRESS_DISABLE;
  hi2c4.Init.OwnAddress2 = 0;
  hi2c4.Init.OwnAddress2Masks = I2C_OA2_NOMASK;
  hi2c4.Init.GeneralCallMode = I2C_GENERALCALL_DISABLE;
  hi2c4.Init.NoStretchMode = I2C_NOSTRETCH_DISABLE;
  if (HAL_I2C_Init(&hi2c4) != HAL_OK)
  {
    Error_Handler();
  }
  /** Configure Analogue filter
  */
  if (HAL_I2CEx_ConfigAnalogFilter(&hi2c4, I2C_ANALOGFILTER_ENABLE) != HAL_OK)
  {
    Error_Handler();
  }
  /** Configure Digital filter
  */
  if (HAL_I2CEx_ConfigDigitalFilter(&hi2c4, 0) != HAL_OK)
  {
    Error_Handler();
  }

}

static void MX_LTDC_Init(void)
{

  LTDC_LayerCfgTypeDef pLayerCfg = {0};
  LTDC_LayerCfgTypeDef pLayerCfg1 = {0};

  hltdc.Instance = LTDC;
  hltdc.Init.HSPolarity = LTDC_HSPOLARITY_AL;
  hltdc.Init.VSPolarity = LTDC_VSPOLARITY_AL;
  hltdc.Init.DEPolarity = LTDC_DEPOLARITY_AL;
  hltdc.Init.PCPolarity = LTDC_PCPOLARITY_IPC;
  hltdc.Init.HorizontalSync = 0;
  hltdc.Init.VerticalSync = 0;
  hltdc.Init.AccumulatedHBP = 1;
  hltdc.Init.AccumulatedVBP = 1;
  hltdc.Init.AccumulatedActiveW = 801;
  hltdc.Init.AccumulatedActiveH = 481;
  hltdc.Init.TotalWidth = 802;
  hltdc.Init.TotalHeigh = 482;
  hltdc.Init.Backcolor.Blue = 0;
  hltdc.Init.Backcolor.Green = 0;
  hltdc.Init.Backcolor.Red = 0;
  if (HAL_LTDC_Init(&hltdc) != HAL_OK)
  {
    Error_Handler();
  }
  pLayerCfg.WindowX0 = 0;
  pLayerCfg.WindowX1 = 0;
  pLayerCfg.WindowY0 = 0;
  pLayerCfg.WindowY1 = 0;
  pLayerCfg.PixelFormat = LTDC_PIXEL_FORMAT_ARGB8888;
  pLayerCfg.Alpha = 0;
  pLayerCfg.Alpha0 = 0;
  pLayerCfg.BlendingFactor1 = LTDC_BLENDING_FACTOR1_CA;
  pLayerCfg.BlendingFactor2 = LTDC_BLENDING_FACTOR2_CA;
  pLayerCfg.FBStartAdress = 0;
  pLayerCfg.ImageWidth = 0;
  pLayerCfg.ImageHeight = 0;
  pLayerCfg.Backcolor.Blue = 0;
  pLayerCfg.Backcolor.Green = 0;
  pLayerCfg.Backcolor.Red = 0;
  if (HAL_LTDC_ConfigLayer(&hltdc, &pLayerCfg, 0) != HAL_OK)
  {
    Error_Handler();
  }
  pLayerCfg1.WindowX0 = 0;
  pLayerCfg1.WindowX1 = 0;
  pLayerCfg1.WindowY0 = 0;
  pLayerCfg1.WindowY1 = 0;
  pLayerCfg1.PixelFormat = LTDC_PIXEL_FORMAT_ARGB8888;
  pLayerCfg1.Alpha = 0;
  pLayerCfg1.Alpha0 = 0;
  pLayerCfg1.BlendingFactor1 = LTDC_BLENDING_FACTOR1_CA;
  pLayerCfg1.BlendingFactor2 = LTDC_BLENDING_FACTOR2_CA;
  pLayerCfg1.FBStartAdress = 0;
  pLayerCfg1.ImageWidth = 0;
  pLayerCfg1.ImageHeight = 0;
  pLayerCfg1.Backcolor.Blue = 0;
  pLayerCfg1.Backcolor.Green = 0;
  pLayerCfg1.Backcolor.Red = 0;
  if (HAL_LTDC_ConfigLayer(&hltdc, &pLayerCfg1, 1) != HAL_OK)
  {
    Error_Handler();
  }
  if (HAL_LTDC_SetPitch(&hltdc, 0, 0) != HAL_OK)
  {
    Error_Handler();
  }
  if (HAL_LTDC_SetPitch(&hltdc, 0, 1) != HAL_OK)
  {
    Error_Handler();
  }

}

static void MX_RTC_Init(void)
{

  RTC_TamperTypeDef sTamper = {0};

  /** Initialize RTC Only
  */
  hrtc.Instance = RTC;
  hrtc.Init.HourFormat = RTC_HOURFORMAT_24;
  hrtc.Init.AsynchPrediv = 127;
  hrtc.Init.SynchPrediv = 255;
  hrtc.Init.OutPut = RTC_OUTPUT_DISABLE;
  hrtc.Init.OutPutRemap = RTC_OUTPUT_REMAP_NONE;
  hrtc.Init.OutPutPolarity = RTC_OUTPUT_POLARITY_HIGH;
  hrtc.Init.OutPutType = RTC_OUTPUT_TYPE_OPENDRAIN;
  if (HAL_RTC_Init(&hrtc) != HAL_OK)
  {
    Error_Handler();
  }
  /** Enable the RTC Tamper 1
  */
  sTamper.Tamper = RTC_TAMPER_1;
  sTamper.Trigger = RTC_TAMPERTRIGGER_RISINGEDGE;
  sTamper.NoErase = RTC_TAMPER_ERASE_BACKUP_ENABLE;
  sTamper.MaskFlag = RTC_TAMPERMASK_FLAG_DISABLE;
  sTamper.Filter = RTC_TAMPERFILTER_DISABLE;
  sTamper.SamplingFrequency = RTC_TAMPERSAMPLINGFREQ_RTCCLK_DIV32768;
  sTamper.PrechargeDuration = RTC_TAMPERPRECHARGEDURATION_1RTCCLK;
  sTamper.TamperPullUp = RTC_TAMPER_PULLUP_ENABLE;
  sTamper.TimeStampOnTamperDetection = RTC_TIMESTAMPONTAMPERDETECTION_ENABLE;
  if (HAL_RTCEx_SetTamper(&hrtc, &sTamper) != HAL_OK)
  {
    Error_Handler();
  }

}

static void MX_SAI1_Init(void)
{

  hsai_BlockA1.Instance = SAI1_Block_A;
  hsai_BlockA1.Init.Protocol = SAI_FREE_PROTOCOL;
  hsai_BlockA1.Init.AudioMode = SAI_MODEMASTER_TX;
  hsai_BlockA1.Init.DataSize = SAI_DATASIZE_8;
  hsai_BlockA1.Init.FirstBit = SAI_FIRSTBIT_MSB;
  hsai_BlockA1.Init.ClockStrobing = SAI_CLOCKSTROBING_FALLINGEDGE;
  hsai_BlockA1.Init.Synchro = SAI_ASYNCHRONOUS;
  hsai_BlockA1.Init.OutputDrive = SAI_OUTPUTDRIVE_DISABLE;
  hsai_BlockA1.Init.NoDivider = SAI_MASTERDIVIDER_ENABLE;
  hsai_BlockA1.Init.MckOverSampling = SAI_MCK_OVERSAMPLING_DISABLE;
  hsai_BlockA1.Init.FIFOThreshold = SAI_FIFOTHRESHOLD_EMPTY;
  hsai_BlockA1.Init.AudioFrequency = SAI_AUDIO_FREQUENCY_192K;
  hsai_BlockA1.Init.SynchroExt = SAI_SYNCEXT_DISABLE;
  hsai_BlockA1.Init.MonoStereoMode = SAI_STEREOMODE;
  hsai_BlockA1.Init.CompandingMode = SAI_NOCOMPANDING;
  hsai_BlockA1.Init.TriState = SAI_OUTPUT_NOTRELEASED;
  hsai_BlockA1.Init.PdmInit.Activation = DISABLE;
  hsai_BlockA1.Init.PdmInit.MicPairsNbr = 0;
  hsai_BlockA1.Init.PdmInit.ClockEnable = SAI_PDM_CLOCK1_ENABLE;
  hsai_BlockA1.FrameInit.FrameLength = 8;
  hsai_BlockA1.FrameInit.ActiveFrameLength = 1;
  hsai_BlockA1.FrameInit.FSDefinition = SAI_FS_STARTFRAME;
  hsai_BlockA1.FrameInit.FSPolarity = SAI_FS_ACTIVE_LOW;
  hsai_BlockA1.FrameInit.FSOffset = SAI_FS_FIRSTBIT;
  hsai_BlockA1.SlotInit.FirstBitOffset = 0;
  hsai_BlockA1.SlotInit.SlotSize = SAI_SLOTSIZE_DATASIZE;
  hsai_BlockA1.SlotInit.SlotNumber = 1;
  hsai_BlockA1.SlotInit.SlotActive = 0x00000000;
  if (HAL_SAI_Init(&hsai_BlockA1) != HAL_OK)
  {
    Error_Handler();
  }
  hsai_BlockB1.Instance = SAI1_Block_B;
  hsai_BlockB1.Init.Protocol = SAI_FREE_PROTOCOL;
  hsai_BlockB1.Init.AudioMode = SAI_MODESLAVE_RX;
  hsai_BlockB1.Init.DataSize = SAI_DATASIZE_8;
  hsai_BlockB1.Init.FirstBit = SAI_FIRSTBIT_MSB;
  hsai_BlockB1.Init.ClockStrobing = SAI_CLOCKSTROBING_FALLINGEDGE;
  hsai_BlockB1.Init.Synchro = SAI_SYNCHRONOUS;
  hsai_BlockB1.Init.OutputDrive = SAI_OUTPUTDRIVE_DISABLE;
  hsai_BlockB1.Init.FIFOThreshold = SAI_FIFOTHRESHOLD_EMPTY;
  hsai_BlockB1.Init.SynchroExt = SAI_SYNCEXT_DISABLE;
  hsai_BlockB1.Init.MonoStereoMode = SAI_STEREOMODE;
  hsai_BlockB1.Init.CompandingMode = SAI_NOCOMPANDING;
  hsai_BlockB1.Init.TriState = SAI_OUTPUT_NOTRELEASED;
  hsai_BlockB1.Init.PdmInit.Activation = DISABLE;
  hsai_BlockB1.Init.PdmInit.MicPairsNbr = 0;
  hsai_BlockB1.Init.PdmInit.ClockEnable = SAI_PDM_CLOCK1_ENABLE;
  hsai_BlockB1.FrameInit.FrameLength = 8;
  hsai_BlockB1.FrameInit.ActiveFrameLength = 1;
  hsai_BlockB1.FrameInit.FSDefinition = SAI_FS_STARTFRAME;
  hsai_BlockB1.FrameInit.FSPolarity = SAI_FS_ACTIVE_LOW;
  hsai_BlockB1.FrameInit.FSOffset = SAI_FS_FIRSTBIT;
  hsai_BlockB1.SlotInit.FirstBitOffset = 0;
  hsai_BlockB1.SlotInit.SlotSize = SAI_SLOTSIZE_DATASIZE;
  hsai_BlockB1.SlotInit.SlotNumber = 1;
  hsai_BlockB1.SlotInit.SlotActive = 0x00000000;
  if (HAL_SAI_Init(&hsai_BlockB1) != HAL_OK)
  {
    Error_Handler();
  }

}

static void MX_SDMMC1_SD_Init(void)
{

  hsd1.Instance = SDMMC1;
  hsd1.Init.ClockEdge = SDMMC_CLOCK_EDGE_RISING;
  hsd1.Init.ClockPowerSave = SDMMC_CLOCK_POWER_SAVE_DISABLE;
  hsd1.Init.BusWide = SDMMC_BUS_WIDE_4B;
  hsd1.Init.HardwareFlowControl = SDMMC_HARDWARE_FLOW_CONTROL_DISABLE;
  hsd1.Init.ClockDiv = 0;
  hsd1.Init.Transceiver = SDMMC_TRANSCEIVER_DISABLE;
  if (HAL_SD_Init(&hsd1) != HAL_OK)
  {
    Error_Handler();
  }

}

static void MX_SPI1_Init(void)
{

  /* SPI1 parameter configuration*/
  hspi1.Instance = SPI1;
  hspi1.Init.Mode = SPI_MODE_MASTER;
  hspi1.Init.Direction = SPI_DIRECTION_2LINES;
  hspi1.Init.DataSize = SPI_DATASIZE_8BIT;
  hspi1.Init.CLKPolarity = SPI_POLARITY_LOW;
  hspi1.Init.CLKPhase = SPI_PHASE_2EDGE;
  hspi1.Init.NSS = SPI_NSS_SOFT;
  hspi1.Init.BaudRatePrescaler = SPI_BAUDRATEPRESCALER_64;
  hspi1.Init.FirstBit = SPI_FIRSTBIT_MSB;
  hspi1.Init.TIMode = SPI_TIMODE_DISABLE;
  hspi1.Init.CRCCalculation = SPI_CRCCALCULATION_DISABLE;
  hspi1.Init.CRCPolynomial = 7;
  hspi1.Init.CRCLength = SPI_CRC_LENGTH_DATASIZE;
  hspi1.Init.NSSPMode = SPI_NSS_PULSE_DISABLE;
  if (HAL_SPI_Init(&hspi1) != HAL_OK)
  {
    Error_Handler();
  }

}

static void MX_SPI2_Init(void)
{

  /* SPI2 parameter configuration*/
  hspi2.Instance = SPI2;
  hspi2.Init.Mode = SPI_MODE_MASTER;
  hspi2.Init.Direction = SPI_DIRECTION_2LINES;
  hspi2.Init.DataSize = SPI_DATASIZE_8BIT;
  hspi2.Init.CLKPolarity = SPI_POLARITY_LOW;
  hspi2.Init.CLKPhase = SPI_PHASE_2EDGE;
  hspi2.Init.NSS = SPI_NSS_SOFT;
  hspi2.Init.BaudRatePrescaler = SPI_BAUDRATEPRESCALER_64;
  hspi2.Init.FirstBit = SPI_FIRSTBIT_MSB;
  hspi2.Init.TIMode = SPI_TIMODE_DISABLE;
  hspi2.Init.CRCCalculation = SPI_CRCCALCULATION_DISABLE;
  hspi2.Init.CRCPolynomial = 7;
  hspi2.Init.CRCLength = SPI_CRC_LENGTH_DATASIZE;
  hspi2.Init.NSSPMode = SPI_NSS_PULSE_DISABLE;
  if (HAL_SPI_Init(&hspi2) != HAL_OK)
  {
    Error_Handler();
  }

}

static void MX_SPI3_Init(void)
{

  /* SPI3 parameter configuration*/
  hspi3.Instance = SPI3;
  hspi3.Init.Mode = SPI_MODE_MASTER;
  hspi3.Init.Direction = SPI_DIRECTION_2LINES;
  hspi3.Init.DataSize = SPI_DATASIZE_8BIT;
  hspi3.Init.CLKPolarity = SPI_POLARITY_HIGH;
  hspi3.Init.CLKPhase = SPI_PHASE_2EDGE;
  hspi3.Init.NSS = SPI_NSS_SOFT;
  hspi3.Init.BaudRatePrescaler = SPI_BAUDRATEPRESCALER_16;
  hspi3.Init.FirstBit = SPI_FIRSTBIT_MSB;
  hspi3.Init.TIMode = SPI_TIMODE_DISABLE;
  hspi3.Init.CRCCalculation = SPI_CRCCALCULATION_DISABLE;
  hspi3.Init.CRCPolynomial = 7;
  hspi3.Init.CRCLength = SPI_CRC_LENGTH_DATASIZE;
  hspi3.Init.NSSPMode = SPI_NSS_PULSE_DISABLE;
  if (HAL_SPI_Init(&hspi3) != HAL_OK)
  {
    Error_Handler();
  }

}

static void MX_TIM2_Init(void)
{

  TIM_MasterConfigTypeDef sMasterConfig = {0};
  TIM_OC_InitTypeDef sConfigOC = {0};

  htim2.Instance = TIM2;
  htim2.Init.Prescaler = 0;
  htim2.Init.CounterMode = TIM_COUNTERMODE_UP;
  htim2.Init.Period = 4294967295;
  htim2.Init.ClockDivision = TIM_CLOCKDIVISION_DIV1;
  htim2.Init.AutoReloadPreload = TIM_AUTORELOAD_PRELOAD_DISABLE;
  if (HAL_TIM_PWM_Init(&htim2) != HAL_OK)
  {
    Error_Handler();
  }
  sMasterConfig.MasterOutputTrigger = TIM_TRGO_RESET;
  sMasterConfig.MasterSlaveMode = TIM_MASTERSLAVEMODE_DISABLE;
  if (HAL_TIMEx_MasterConfigSynchronization(&htim2, &sMasterConfig) != HAL_OK)
  {
    Error_Handler();
  }
  sConfigOC.OCMode = TIM_OCMODE_PWM1;
  sConfigOC.Pulse = 0;
  sConfigOC.OCPolarity = TIM_OCPOLARITY_HIGH;
  sConfigOC.OCFastMode = TIM_OCFAST_DISABLE;
  if (HAL_TIM_PWM_ConfigChannel(&htim2, &sConfigOC, TIM_CHANNEL_1) != HAL_OK)
  {
    Error_Handler();
  }
  HAL_TIM_MspPostInit(&htim2);

}

static void MX_TIM5_Init(void)
{

  TIM_MasterConfigTypeDef sMasterConfig = {0};
  TIM_OC_InitTypeDef sConfigOC = {0};

  htim5.Instance = TIM5;
  htim5.Init.Prescaler = 0;
  htim5.Init.CounterMode = TIM_COUNTERMODE_UP;
  htim5.Init.Period = 4294967295;
  htim5.Init.ClockDivision = TIM_CLOCKDIVISION_DIV1;
  htim5.Init.AutoReloadPreload = TIM_AUTORELOAD_PRELOAD_DISABLE;
  if (HAL_TIM_OC_Init(&htim5) != HAL_OK)
  {
    Error_Handler();
  }
  if (HAL_TIM_OnePulse_Init(&htim5, TIM_OPMODE_SINGLE) != HAL_OK)
  {
    Error_Handler();
  }
  sMasterConfig.MasterOutputTrigger = TIM_TRGO_RESET;
  sMasterConfig.MasterSlaveMode = TIM_MASTERSLAVEMODE_DISABLE;
  if (HAL_TIMEx_MasterConfigSynchronization(&htim5, &sMasterConfig) != HAL_OK)
  {
    Error_Handler();
  }
  sConfigOC.OCMode = TIM_OCMODE_FORCED_ACTIVE;
  sConfigOC.Pulse = 0;
  sConfigOC.OCPolarity = TIM_OCPOLARITY_HIGH;
  sConfigOC.OCFastMode = TIM_OCFAST_DISABLE;
  if (HAL_TIM_OC_ConfigChannel(&htim5, &sConfigOC, TIM_CHANNEL_1) != HAL_OK)
  {
    Error_Handler();
  }
  HAL_TIM_MspPostInit(&htim5);

}

static void MX_USART2_UART_Init(void)
{

  huart2.Instance = USART2;
  huart2.Init.BaudRate = 115200;
  huart2.Init.WordLength = UART_WORDLENGTH_8B;
  huart2.Init.StopBits = UART_STOPBITS_1;
  huart2.Init.Parity = UART_PARITY_NONE;
  huart2.Init.Mode = UART_MODE_TX_RX;
  huart2.Init.HwFlowCtl = UART_HWCONTROL_RTS;
  huart2.Init.OverSampling = UART_OVERSAMPLING_16;
  huart2.Init.OneBitSampling = UART_ONE_BIT_SAMPLE_DISABLE;
  huart2.Init.ClockPrescaler = UART_PRESCALER_DIV1;
  huart2.AdvancedInit.AdvFeatureInit = UART_ADVFEATURE_NO_INIT;
  if (HAL_UART_Init(&huart2) != HAL_OK)
  {
    Error_Handler();
  }
  if (HAL_UARTEx_SetTxFifoThreshold(&huart2, UART_TXFIFO_THRESHOLD_1_8) != HAL_OK)
  {
    Error_Handler();
  }
  if (HAL_UARTEx_SetRxFifoThreshold(&huart2, UART_RXFIFO_THRESHOLD_1_8) != HAL_OK)
  {
    Error_Handler();
  }
  if (HAL_UARTEx_DisableFifoMode(&huart2) != HAL_OK)
  {
    Error_Handler();
  }

}

static void MX_USART3_UART_Init(void)
{

  huart3.Instance = USART3;
  huart3.Init.BaudRate = 115200;
  huart3.Init.WordLength = UART_WORDLENGTH_8B;
  huart3.Init.StopBits = UART_STOPBITS_1;
  huart3.Init.Parity = UART_PARITY_NONE;
  huart3.Init.Mode = UART_MODE_TX_RX;
  huart3.Init.HwFlowCtl = UART_HWCONTROL_RTS_CTS;
  huart3.Init.OverSampling = UART_OVERSAMPLING_16;
  huart3.Init.OneBitSampling = UART_ONE_BIT_SAMPLE_DISABLE;
  huart3.Init.ClockPrescaler = UART_PRESCALER_DIV1;
  huart3.AdvancedInit.AdvFeatureInit = UART_ADVFEATURE_NO_INIT;
  if (HAL_UART_Init(&huart3) != HAL_OK)
  {
    Error_Handler();
  }
  if (HAL_UARTEx_SetTxFifoThreshold(&huart3, UART_TXFIFO_THRESHOLD_1_8) != HAL_OK)
  {
    Error_Handler();
  }
  if (HAL_UARTEx_SetRxFifoThreshold(&huart3, UART_RXFIFO_THRESHOLD_1_8) != HAL_OK)
  {
    Error_Handler();
  }
  if (HAL_UARTEx_DisableFifoMode(&huart3) != HAL_OK)
  {
    Error_Handler();
  }

}

static void MX_USB_OTG_FS_PCD_Init(void)
{

  hpcd_USB_OTG_FS.Instance = USB_OTG_FS;
  hpcd_USB_OTG_FS.Init.dev_endpoints = 6;
  hpcd_USB_OTG_FS.Init.phy_itface = PCD_PHY_EMBEDDED;
  hpcd_USB_OTG_FS.Init.Sof_enable = DISABLE;
  hpcd_USB_OTG_FS.Init.low_power_enable = DISABLE;
  hpcd_USB_OTG_FS.Init.lpm_enable = DISABLE;
  hpcd_USB_OTG_FS.Init.battery_charging_enable = DISABLE;
  hpcd_USB_OTG_FS.Init.use_dedicated_ep1 = DISABLE;
  hpcd_USB_OTG_FS.Init.vbus_sensing_enable = DISABLE;
  if (HAL_PCD_Init(&hpcd_USB_OTG_FS) != HAL_OK)
  {
    Error_Handler();
  }

}

static void MX_DMA_Init(void)
{

  /* DMA controller clock enable */
  __HAL_RCC_DMAMUX1_CLK_ENABLE();
  __HAL_RCC_DMA1_CLK_ENABLE();

  /* DMA interrupt init */
  /* DMA1_Channel1_IRQn interrupt configuration */
  HAL_NVIC_SetPriority(DMA1_Channel1_IRQn, 0, 0);
  HAL_NVIC_EnableIRQ(DMA1_Channel1_IRQn);

}

static void MX_GPIO_Init(void)
{
  GPIO_InitTypeDef GPIO_InitStruct = {0};

  /* GPIO Ports Clock Enable */
  __HAL_RCC_GPIOE_CLK_ENABLE();
  __HAL_RCC_GPIOB_CLK_ENABLE();
  __HAL_RCC_GPIOH_CLK_ENABLE();
  __HAL_RCC_GPIOC_CLK_ENABLE();
  __HAL_RCC_GPIOA_CLK_ENABLE();
  __HAL_RCC_GPIOD_CLK_ENABLE();
  __HAL_RCC_GPIOG_CLK_ENABLE();
  HAL_PWREx_EnableVddIO2();
  __HAL_RCC_GPIOF_CLK_ENABLE();

  /*Configure GPIO pin Output Level */
  HAL_GPIO_WritePin(GPIOE, LED1_Pin|DCDC_2_EN_Pin, GPIO_PIN_RESET);

  /*Configure GPIO pin Output Level */
  HAL_GPIO_WritePin(GPIOD, LED2_Pin|WIFI_WAKEUP_Pin|CS_DH_Pin|EX_RESET_Pin, GPIO_PIN_RESET);

  /*Configure GPIO pin Output Level */
  HAL_GPIO_WritePin(BLE_RST_GPIO_Port, BLE_RST_Pin, GPIO_PIN_RESET);

  /*Configure GPIO pin Output Level */
  HAL_GPIO_WritePin(WIFI_RST_GPIO_Port, WIFI_RST_Pin, GPIO_PIN_RESET);

  /*Configure GPIO pin Output Level */
  HAL_GPIO_WritePin(GPIOF, CS_WIFI_Pin|C_EN_Pin|CS_ADWB_Pin|STSAFE_RESET_Pin
                          |WIFI_BOOT0_Pin|CS_DHC_Pin|SEL3_4_Pin, GPIO_PIN_RESET);

  /*Configure GPIO pin Output Level */
  HAL_GPIO_WritePin(GPIOG, BLE_SPI_CS_Pin|SEL1_2_Pin, GPIO_PIN_RESET);

  /*Configure GPIO pin Output Level */
  HAL_GPIO_WritePin(GPIOB, SPI2_MOSI_p2_Pin|PB11_Pin, GPIO_PIN_RESET);

  /*Configure GPIO pins : BOOT0_PE0_Pin BLE_TEST8_Pin */
  GPIO_InitStruct.Pin = BOOT0_PE0_Pin|BLE_TEST8_Pin;
  GPIO_InitStruct.Mode = GPIO_MODE_INPUT;
  GPIO_InitStruct.Pull = GPIO_NOPULL;
  HAL_GPIO_Init(GPIOE, &GPIO_InitStruct);

  /*Configure GPIO pins : PB9_Pin PB8_Pin PB14_Pin CHRGB0_Pin */
  GPIO_InitStruct.Pin = PB9_Pin|PB8_Pin|PB14_Pin|CHRGB0_Pin;
  GPIO_InitStruct.Mode = GPIO_MODE_ANALOG;
  GPIO_InitStruct.Pull = GPIO_NOPULL;
  HAL_GPIO_Init(GPIOB, &GPIO_InitStruct);

  /*Configure GPIO pin : BOOT0_PE0H3_Pin */
  GPIO_InitStruct.Pin = BOOT0_PE0H3_Pin;
  GPIO_InitStruct.Mode = GPIO_MODE_INPUT;
  GPIO_InitStruct.Pull = GPIO_NOPULL;
  HAL_GPIO_Init(BOOT0_PE0H3_GPIO_Port, &GPIO_InitStruct);

  /*Configure GPIO pins : BLE_TEST9_Pin WIFI_DRDY_Pin INT1_DHC_Pin INT_STT_Pin
                           INT1_ADWB_Pin */
  GPIO_InitStruct.Pin = BLE_TEST9_Pin|WIFI_DRDY_Pin|INT1_DHC_Pin|INT_STT_Pin
                          |INT1_ADWB_Pin;
  GPIO_InitStruct.Mode = GPIO_MODE_IT_RISING;
  GPIO_InitStruct.Pull = GPIO_NOPULL;
  HAL_GPIO_Init(GPIOE, &GPIO_InitStruct);

  /*Configure GPIO pins : LED1_Pin DCDC_2_EN_Pin */
  GPIO_InitStruct.Pin = LED1_Pin|DCDC_2_EN_Pin;
  GPIO_InitStruct.Mode = GPIO_MODE_OUTPUT_PP;
  GPIO_InitStruct.Pull = GPIO_NOPULL;
  GPIO_InitStruct.Speed = GPIO_SPEED_FREQ_LOW;
  HAL_GPIO_Init(GPIOE, &GPIO_InitStruct);

  /*Configure GPIO pins : LED2_Pin WIFI_WAKEUP_Pin CS_DH_Pin EX_RESET_Pin */
  GPIO_InitStruct.Pin = LED2_Pin|WIFI_WAKEUP_Pin|CS_DH_Pin|EX_RESET_Pin;
  GPIO_InitStruct.Mode = GPIO_MODE_OUTPUT_PP;
  GPIO_InitStruct.Pull = GPIO_NOPULL;
  GPIO_InitStruct.Speed = GPIO_SPEED_FREQ_LOW;
  HAL_GPIO_Init(GPIOD, &GPIO_InitStruct);

  /*Configure GPIO pins : PA10_Pin PA9_Pin PA0_Pin PA1_Pin */
  GPIO_InitStruct.Pin = PA10_Pin|PA9_Pin|PA0_Pin|PA1_Pin;
  GPIO_InitStruct.Mode = GPIO_MODE_ANALOG;
  GPIO_InitStruct.Pull = GPIO_NOPULL;
  HAL_GPIO_Init(GPIOA, &GPIO_InitStruct);

  /*Configure GPIO pins : PG12_Pin PG10_Pin PG9_Pin */
  GPIO_InitStruct.Pin = PG12_Pin|PG10_Pin|PG9_Pin;
  GPIO_InitStruct.Mode = GPIO_MODE_ANALOG;
  GPIO_InitStruct.Pull = GPIO_NOPULL;
  HAL_GPIO_Init(GPIOG, &GPIO_InitStruct);

  /*Configure GPIO pin : BLE_RST_Pin */
  GPIO_InitStruct.Pin = BLE_RST_Pin;
  GPIO_InitStruct.Mode = GPIO_MODE_OUTPUT_PP;
  GPIO_InitStruct.Pull = GPIO_NOPULL;
  GPIO_InitStruct.Speed = GPIO_SPEED_FREQ_LOW;
  HAL_GPIO_Init(BLE_RST_GPIO_Port, &GPIO_InitStruct);

  /*Configure GPIO pin : WIFI_RST_Pin */
  GPIO_InitStruct.Pin = WIFI_RST_Pin;
  GPIO_InitStruct.Mode = GPIO_MODE_OUTPUT_PP;
  GPIO_InitStruct.Pull = GPIO_NOPULL;
  GPIO_InitStruct.Speed = GPIO_SPEED_FREQ_LOW;
  HAL_GPIO_Init(WIFI_RST_GPIO_Port, &GPIO_InitStruct);

  /*Configure GPIO pins : CS_WIFI_Pin C_EN_Pin CS_ADWB_Pin STSAFE_RESET_Pin
                           WIFI_BOOT0_Pin CS_DHC_Pin SEL3_4_Pin */
  GPIO_InitStruct.Pin = CS_WIFI_Pin|C_EN_Pin|CS_ADWB_Pin|STSAFE_RESET_Pin
                          |WIFI_BOOT0_Pin|CS_DHC_Pin|SEL3_4_Pin;
  GPIO_InitStruct.Mode = GPIO_MODE_OUTPUT_PP;
  GPIO_InitStruct.Pull = GPIO_NOPULL;
  GPIO_InitStruct.Speed = GPIO_SPEED_FREQ_LOW;
  HAL_GPIO_Init(GPIOF, &GPIO_InitStruct);

  /*Configure GPIO pins : INT2_DHC_Pin PGOOD_Pin INT_M_Pin */
  GPIO_InitStruct.Pin = INT2_DHC_Pin|PGOOD_Pin|INT_M_Pin;
  GPIO_InitStruct.Mode = GPIO_MODE_IT_RISING;
  GPIO_InitStruct.Pull = GPIO_NOPULL;
  HAL_GPIO_Init(GPIOF, &GPIO_InitStruct);

  /*Configure GPIO pins : BLE_SPI_CS_Pin SEL1_2_Pin */
  GPIO_InitStruct.Pin = BLE_SPI_CS_Pin|SEL1_2_Pin;
  GPIO_InitStruct.Mode = GPIO_MODE_OUTPUT_PP;
  GPIO_InitStruct.Pull = GPIO_NOPULL;
  GPIO_InitStruct.Speed = GPIO_SPEED_FREQ_LOW;
  HAL_GPIO_Init(GPIOG, &GPIO_InitStruct);

  /*Configure GPIO pins : INT_HTS_Pin BLE_INT_Pin */
  GPIO_InitStruct.Pin = INT_HTS_Pin|BLE_INT_Pin;
  GPIO_InitStruct.Mode = GPIO_MODE_IT_RISING;
  GPIO_InitStruct.Pull = GPIO_NOPULL;
  HAL_GPIO_Init(GPIOG, &GPIO_InitStruct);

  /*Configure GPIO pins : INT2_ADWB_Pin SD_DETECT_Pin */
  GPIO_InitStruct.Pin = INT2_ADWB_Pin|SD_DETECT_Pin;
  GPIO_InitStruct.Mode = GPIO_MODE_INPUT;
  GPIO_InitStruct.Pull = GPIO_NOPULL;
  HAL_GPIO_Init(GPIOB, &GPIO_InitStruct);

  /*Configure GPIO pin : CHRG_Pin */
  GPIO_InitStruct.Pin = CHRG_Pin;
  GPIO_InitStruct.Mode = GPIO_MODE_INPUT;
  GPIO_InitStruct.Pull = GPIO_NOPULL;
  HAL_GPIO_Init(CHRG_GPIO_Port, &GPIO_InitStruct);

  /*Configure GPIO pin : BUTTON_PWR_Pin */
  GPIO_InitStruct.Pin = BUTTON_PWR_Pin;
  GPIO_InitStruct.Mode = GPIO_MODE_IT_RISING;
  GPIO_InitStruct.Pull = GPIO_NOPULL;
  HAL_GPIO_Init(BUTTON_PWR_GPIO_Port, &GPIO_InitStruct);

  /*Configure GPIO pins : SPI2_MOSI_p2_Pin PB11_Pin */
  GPIO_InitStruct.Pin = SPI2_MOSI_p2_Pin|PB11_Pin;
  GPIO_InitStruct.Mode = GPIO_MODE_OUTPUT_PP;
  GPIO_InitStruct.Pull = GPIO_NOPULL;
  GPIO_InitStruct.Speed = GPIO_SPEED_FREQ_LOW;
  HAL_GPIO_Init(GPIOB, &GPIO_InitStruct);

  /*Configure GPIO pin : INT2_DH_Pin */
  GPIO_InitStruct.Pin = INT2_DH_Pin;
  GPIO_InitStruct.Mode = GPIO_MODE_IT_RISING;
  GPIO_InitStruct.Pull = GPIO_NOPULL;
  HAL_GPIO_Init(INT2_DH_GPIO_Port, &GPIO_InitStruct);

  /*Configure GPIO pin : PE12_Pin */
  GPIO_InitStruct.Pin = PE12_Pin;
  GPIO_InitStruct.Mode = GPIO_MODE_ANALOG;
  GPIO_InitStruct.Pull = GPIO_NOPULL;
  HAL_GPIO_Init(PE12_GPIO_Port, &GPIO_InitStruct);

}

/* USER CODE BEGIN 4 */
HAL_StatusTypeDef Init_HTS221(void) {
  /* Check device ID for Humidity sensor */
  whoamI = 0;
  hts221_device_id_get(&hts221Driver, &whoamI);
  /* Configure Humidity sensor */
  if (whoamI == HTS221_ID) {
    /* Enable Block Data Update */
    hts221_block_data_update_set(&hts221Driver, PROPERTY_ENABLE);
    /* Set Output Data Rate */
    hts221_data_rate_set(&hts221Driver, HTS221_ODR_12Hz5);
    hts221_humidity_avg_set(&hts221Driver, HTS221_H_AVG_4);
    hts221_temperature_avg_set(&hts221Driver, HTS221_T_AVG_2);
    /* Device Power On */
    hts221_power_on_set(&hts221Driver, PROPERTY_ENABLE);
    /* Read humidity calibration coefficient */
    hts221_hum_adc_point_0_get(&hts221Driver, &lin_hum.x0);
    hts221_hum_rh_point_0_get(&hts221Driver, &lin_hum.y0);
    hts221_hum_adc_point_1_get(&hts221Driver, &lin_hum.x1);
    hts221_hum_rh_point_1_get(&hts221Driver, &lin_hum.y1);
    /* Read temperature calibration coefficient */
    hts221_temp_adc_point_0_get(&hts221Driver, &lin_temp.x0);
    hts221_temp_deg_point_0_get(&hts221Driver, &lin_temp.y0);
    hts221_temp_adc_point_1_get(&hts221Driver, &lin_temp.x1);
    hts221_temp_deg_point_1_get(&hts221Driver, &lin_temp.y1);
    return HAL_OK;
  } else {
    return HAL_ERROR;
  }
}

static int32_t hts221_read(void *handle, uint8_t reg, uint8_t *bufp, uint16_t len) {
  if (len > 1) reg |= 0x80;
  return HAL_I2C_Mem_Read(handle, HTS221_I2C_ADDRESS, reg, I2C_MEMADD_SIZE_8BIT, bufp, len, 1000);
}

static int32_t hts221_write(void *handle, uint8_t reg, uint8_t *bufp, uint16_t len) {
  if (len > 1) reg |= 0x80;
  return HAL_I2C_Mem_Write(handle, HTS221_I2C_ADDRESS, reg, I2C_MEMADD_SIZE_8BIT, bufp, len, 1000);
}
/* USER CODE END 4 */

void Error_Handler(void)
{
  __disable_irq();
  while (1)
  {
  }
}

/************************ (C) COPYRIGHT STMicroelectronics *****END OF FILE****/
